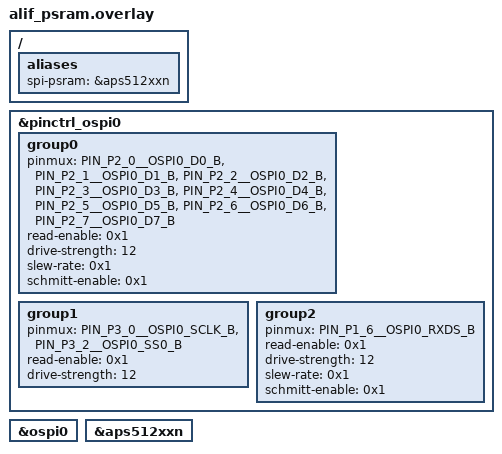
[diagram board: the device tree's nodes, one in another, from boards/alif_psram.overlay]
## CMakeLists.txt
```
cmake_minimum_required(VERSION 3.20.0)
find_package(Zephyr REQUIRED HINTS $ENV{ZEPHYR_BASE})
project(hyperram)

if(CONFIG_TEST_XIP_PERFORMANCE)
  target_sources(app PRIVATE src/performance/test_xip_performance.c)
endif()
if(CONFIG_TEST_XIP_STRESS)
  target_sources(app PRIVATE src/STRESS/test_xip_stress.c)
endif()
if(NOT CONFIG_TEST_XIP_PERFORMANCE AND NOT CONFIG_TEST_XIP_STRESS)
  target_sources(app PRIVATE src/main.c)
endif()
target_sources_ifdef(CONFIG_TEST_PSRAM_FLASH_COPY app PRIVATE src/test_flash_to_psram.c)
target_sources_ifdef(CONFIG_TEST_PSRAM app PRIVATE src/test_hyperram.c)
target_sources_ifdef(CONFIG_TEST_HYPERRAM app PRIVATE src/test_s80ks2564.c)
```

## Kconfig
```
# Copyright (C) 2026 Alif Semiconductor - All Rights Reserved.
# Use, distribution and modification of this code is permitted under the
# terms stated in the Alif Semiconductor Software License Agreement
#
# You should have received a copy of the Alif Semiconductor Software
# License Agreement with this file. If not, please write to:
# contact@alifsemi.com, or visit: https://alifsemi.com/license

choice XIP_DEVICE
	prompt "XIP device under test"
	optional
	default TEST_HYPERRAM
	help
	  Selects which device-specific cases are built on top of the shared
	  XIP suite in src/main.c. HyperRAM (S80KS2564) is the default.
	  Pass CONFIG_TEST_PSRAM=y for the APS512XXN cases, or
	  CONFIG_TEST_ISSI_HYPERRAM=y for the shared suite on ISSI IS66.
	  With neither set, only the shared cases run.

config TEST_PSRAM
	bool "APS512XXN PSRAM"
	help
	  Build src/test_hyperram.c (APS512XXN identity and latency-code vs
	  bus-speed). Use boards/alif_psram.overlay. The shared XIP cases in
	  src/main.c are still built. Select this explicitly for APS512
	  images, including the flash-to-PSRAM copy.

config TEST_HYPERRAM
	bool "S80KS2564 HyperRAM"
	help
	  Build src/test_s80ks2564.c (datasheet identity, tCSM, RWDS, and
	  refresh). Use boards/alif_hex_s80ks.overlay. This is the default
	  device for the suite. The shared XIP cases in src/main.c are
	  still built.

config TEST_ISSI_HYPERRAM
	bool "ISSI IS66 HyperRAM"
	help
	  Run the shared XIP suite only. ISSI IS66 has no latency property,
	  so the S80KS and APS512 files are not built. Use
	  boards/alif_b1_issi_hyperram.overlay on the B1 dev kit.
	  Eight-bit stores are skipped because XiP writes are 16-bit frames.

endchoice

config TEST_PSRAM_FULL_CHIP
	bool "Walk the entire PSRAM in the full-memory XIP test"
	depends on TEST_PSRAM
	help
	  Build only test_full_memory_rw_test, which writes and verifies
	  every byte of DT property size (64 MiB on APS512XXN). The other
	  XIP cases are not registered. Leave disabled for functional CI;
	  enable only on bring-up.

config TEST_HYPERRAM_FULL_CHIP
	bool "Walk the entire HyperRAM in the full-memory XIP test"
	depends on TEST_HYPERRAM
	help
	  Build only test_full_memory_rw_test, which writes and verifies
	  every byte of DT property size (32 MiB on S80KS2564). The other
	  XIP cases are not registered. Leave disabled for functional CI;
	  enable only on bring-up.

config TEST_XIP_PERFORMANCE
	bool "XIP bandwidth and latency tests"
	help
	  Build src/performance/test_xip_performance.c. Leave disabled for
	  the functional suite. The window stays non-cacheable.

config TEST_XIP_STRESS
	bool "XIP stress tests"
	help
	  Build src/STRESS/test_xip_stress.c. Leave disabled for the
	  functional suite. With CONFIG_TEST_PSRAM=y this is the seven
	  stress cases plus the two APS checks.

config TEST_PSRAM_FLASH_COPY
	bool "OSPI flash to PSRAM XiP copy tests"
	help
	  Build the flash-to-PSRAM copy cases next to the XIP suite.
	  PSRAM is boards/alif_psram.overlay. Flash is the ospi-flash snippet.
	  On E8 those are separate controllers (OSPI0 PSRAM, OSPI1 flash).
	  Power management is not used.

config TEST_PSRAM_FLASH_COPY_FULL
	bool "Also copy a preprogrammed 4MB test.bin from flash offset 0"
	depends on TEST_PSRAM_FLASH_COPY
	help
	  Add the sample's 4MB copy. OSPI flash offset 0 must contain the
	  image from gen_test_bin.py --size 4M. Leave disabled for the
	  self-contained suite, which programs its own image at 0x10000.

source "Kconfig.zephyr"
```

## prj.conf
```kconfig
CONFIG_STDOUT_CONSOLE=y
CONFIG_PRINTK=y
CONFIG_LOG=y
CONFIG_ARM_MPU=y
CONFIG_CPU_HAS_CUSTOM_FIXED_SOC_MPU_REGIONS=y
CONFIG_EVENTS=y
CONFIG_MAIN_STACK_SIZE=40960
CONFIG_ZTEST_STACK_SIZE=40960
CONFIG_ZTEST=y

CONFIG_MEMC=y
CONFIG_MEMC_OSPI_ALIF=y
CONFIG_USE_ALIF_HAL_OSPI=y
CONFIG_MEMC_LOG_LEVEL_INF=y

CONFIG_HEAP_MEM_POOL_SIZE=65536
```

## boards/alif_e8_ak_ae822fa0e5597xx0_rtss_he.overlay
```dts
/* Copyright (C) Alif Semiconductor - All Rights Reserved.
 * Use, distribution and modification of this code is permitted under the
 * terms stated in the Alif Semiconductor Software License Agreement
 *
 * You should have received a copy of the Alif Semiconductor Software
 * License Agreement with this file. If not, please write to:
 * contact@alifsemi.com, or visit: https://alifsemi.com/license
 */

/*
 * E8 AppKit HSPI0: 16 data lines + dual RWDS. Applied automatically for
 * alif_e8_ak/.../rtss_he on top of alif_psram.overlay.
 */

&pinctrl {
	pinctrl_ospi0:pinctrl_ospi0 {
		group0 {
			pinmux = < PIN_P2_0__OSPI0_D0_B >,
				 < PIN_P2_1__OSPI0_D1_B >,
				 < PIN_P2_2__OSPI0_D2_B >,
				 < PIN_P2_3__OSPI0_D3_B >,
				 < PIN_P2_4__OSPI0_D4_B >,
				 < PIN_P2_5__OSPI0_D5_B >,
				 < PIN_P2_6__OSPI0_D6_B >,
				 < PIN_P2_7__OSPI0_D7_B >,
				 < PIN_P16_0__OSPI0_D8_B >,
				 < PIN_P16_1__OSPI0_D9_B >,
				 < PIN_P16_2__OSPI0_D10_B >,
				 < PIN_P16_3__OSPI0_D11_B >,
				 < PIN_P16_4__OSPI0_D12_B >,
				 < PIN_P16_5__OSPI0_D13_B >,
				 < PIN_P16_6__OSPI0_D14_B >,
				 < PIN_P16_7__OSPI0_D15_B >;
			read-enable = <0x1>;
			drive-strength = <12>;
			slew-rate = <0x1>;
			schmitt-enable = <0x1>;
		};
		group1 {
			pinmux = < PIN_P3_0__OSPI0_SCLK_B >,
				 < PIN_P3_2__OSPI0_SS0_B >;
			read-enable = <0x1>;
			drive-strength = <12>;
		};
		group2 {
			pinmux = < PIN_P1_6__OSPI0_RXDS_B >,
				 < PIN_P8_5__OSPI0_RXDS1_A >;
			read-enable = <0x1>;
			drive-strength = <12>;
			slew-rate = <0x1>;
			schmitt-enable = <0x1>;
		};
	};
};

&aps512xxn {
	x16-data-transfer-mode;
};
```

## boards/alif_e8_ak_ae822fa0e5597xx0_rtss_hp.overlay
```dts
/* Copyright (C) Alif Semiconductor - All Rights Reserved.
 * Use, distribution and modification of this code is permitted under the
 * terms stated in the Alif Semiconductor Software License Agreement
 *
 * You should have received a copy of the Alif Semiconductor Software
 * License Agreement with this file. If not, please write to:
 * contact@alifsemi.com, or visit: https://alifsemi.com/license
 */

/*
 * E8 AppKit HSPI0: 16 data lines + dual RWDS. Applied automatically for
 * alif_e8_ak/.../rtss_hp on top of alif_psram.overlay.
 */

&pinctrl {
	pinctrl_ospi0:pinctrl_ospi0 {
		group0 {
			pinmux = < PIN_P2_0__OSPI0_D0_B >,
				 < PIN_P2_1__OSPI0_D1_B >,
				 < PIN_P2_2__OSPI0_D2_B >,
				 < PIN_P2_3__OSPI0_D3_B >,
				 < PIN_P2_4__OSPI0_D4_B >,
				 < PIN_P2_5__OSPI0_D5_B >,
				 < PIN_P2_6__OSPI0_D6_B >,
				 < PIN_P2_7__OSPI0_D7_B >,
				 < PIN_P16_0__OSPI0_D8_B >,
				 < PIN_P16_1__OSPI0_D9_B >,
				 < PIN_P16_2__OSPI0_D10_B >,
				 < PIN_P16_3__OSPI0_D11_B >,
				 < PIN_P16_4__OSPI0_D12_B >,
				 < PIN_P16_5__OSPI0_D13_B >,
				 < PIN_P16_6__OSPI0_D14_B >,
				 < PIN_P16_7__OSPI0_D15_B >;
			read-enable = <0x1>;
			drive-strength = <12>;
			slew-rate = <0x1>;
			schmitt-enable = <0x1>;
		};
		group1 {
			pinmux = < PIN_P3_0__OSPI0_SCLK_B >,
				 < PIN_P3_2__OSPI0_SS0_B >;
			read-enable = <0x1>;
			drive-strength = <12>;
		};
		group2 {
			pinmux = < PIN_P1_6__OSPI0_RXDS_B >,
				 < PIN_P8_5__OSPI0_RXDS1_A >;
			read-enable = <0x1>;
			drive-strength = <12>;
			slew-rate = <0x1>;
			schmitt-enable = <0x1>;
		};
	};
};

&aps512xxn {
	x16-data-transfer-mode;
};
```

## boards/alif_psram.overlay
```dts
/* Copyright (C) Alif Semiconductor - All Rights Reserved.
 * Use, distribution and modification of this code is permitted under the
 * terms stated in the Alif Semiconductor Software License Agreement
 *
 * You should have received a copy of the Alif Semiconductor Software
 * License Agreement with this file. If not, please write to:
 * contact@alifsemi.com, or visit: https://alifsemi.com/license
 */

/*
 * For OSPI0 Test with APS512XXN RAM
 */

/ {
	aliases {
		spi-psram = &aps512xxn;
	};
};

&pinctrl_ospi0 {
	group0 {
		pinmux = <PIN_P2_0__OSPI0_D0_B>,
			 <PIN_P2_1__OSPI0_D1_B>,
			 <PIN_P2_2__OSPI0_D2_B>,
			 <PIN_P2_3__OSPI0_D3_B>,
			 <PIN_P2_4__OSPI0_D4_B>,
			 <PIN_P2_5__OSPI0_D5_B>,
			 <PIN_P2_6__OSPI0_D6_B>,
			 <PIN_P2_7__OSPI0_D7_B>;
		read-enable = <0x1>;
		drive-strength = <12>;
		slew-rate = <0x1>;
		schmitt-enable = <0x1>;
	};
	group1 {
		pinmux = <PIN_P3_0__OSPI0_SCLK_B>,
			 <PIN_P3_2__OSPI0_SS0_B>;
		read-enable = <0x1>;
		drive-strength = <12>;
	};
	group2 {
		pinmux = <PIN_P1_6__OSPI0_RXDS_B>;
		read-enable = <0x1>;
		drive-strength = <12>;
		slew-rate = <0x1>;
		schmitt-enable = <0x1>;
	};
};

&ospi0 {
	status = "okay";
};

&aps512xxn {
	status = "okay";
};
```

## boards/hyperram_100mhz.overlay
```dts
/* Layer on boards/alif_hex_s80ks.overlay.
 * LC4 is valid to 104 MHz (S80KS2564 CR0[7:4], tACC 35 ns).
 */

&ospi1 {
	bus-speed = <100000000>;
};

&s80ks2564 {
	latency = <4>;
};
```

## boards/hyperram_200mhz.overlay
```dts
/* Layer on boards/alif_hex_s80ks.overlay.
 * 200 MHz requires latency 7 (S80KS2564 CR0[7:4], tACC 35 ns).
 */

&ospi1 {
	bus-speed = <200000000>;
};

&s80ks2564 {
	latency = <7>;
};
```

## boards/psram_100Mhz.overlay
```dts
/* Copyright (C) Alif Semiconductor - All Rights Reserved.
 * Use, distribution and modification of this code is permitted under the
 * terms stated in the Alif Semiconductor Software License Agreement
 *
 * You should have received a copy of the Alif Semiconductor Software
 * License Agreement with this file. If not, please write to:
 * contact@alifsemi.com, or visit: https://alifsemi.com/license
 */

/* Layer on boards/alif_psram.overlay. Latency code 4 is valid up to 109 MHz. */

&ospi0 {
	bus-speed = <100000000>;
};

&aps512xxn {
	latency-code = <4>;
};
```

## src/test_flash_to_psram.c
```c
/* Copyright (C) 2026 Alif Semiconductor - All Rights Reserved.
 * Use, distribution and modification of this code is permitted under the
 * terms stated in the Alif Semiconductor Software License Agreement
 *
 * You should have received a copy of the Alif Semiconductor Software
 * License Agreement with this file. If not, please write to:
 * contact@alifsemi.com, or visit: https://alifsemi.com/license
 */

/*
 * Copy an OSPI flash image into the PSRAM XiP window and check the same
 * layout as samples/drivers/spi_flash_to_psram_copy (ALIFPSRM magic,
 * offset-encoded words, CRC32 tail).
 *
 * PSRAM comes from boards/alif_psram.overlay (OSPI0, APS512XXN). Flash comes
 * from the ospi-flash snippet (OSPI1 on E8). The two devices are on separate
 * controllers, so the copy is flash_read() into the PSRAM XiP window. No
 * AIPM / power-management overlay is used.
 */

#include <string.h>

#include <zephyr/device.h>
#include <zephyr/devicetree.h>
#include <zephyr/drivers/flash.h>
#include <zephyr/kernel.h>
#include <zephyr/logging/log.h>
#include <zephyr/sys/crc.h>
#include <zephyr/sys/util.h>
#include <zephyr/ztest.h>

#if !DT_HAS_ALIAS(spi_psram)
#error "Devicetree alias spi-psram is required (boards/alif_psram.overlay)"
#endif

#if !DT_HAS_ALIAS(spi_flash0)
#error "Devicetree alias spi-flash0 is required (snippet ospi-flash)"
#endif

LOG_MODULE_REGISTER(hyperram_flash_copy, LOG_LEVEL_INF);

#define FLASH_NODE        DT_ALIAS(spi_flash0)
#define PSRAM_NODE        DT_ALIAS(spi_psram)
#define PSRAM_CTRL_NODE   DT_PARENT(PSRAM_NODE)

#define FLASH_SECTOR_SIZE DT_PROP(FLASH_NODE, sector_size)
/* 1 KiB image. Erase is still one full sector; the driver rejects a short erase. */
#define COPY_TEST_BYTES   1024U
#define COPY_CHUNK        1024U
#define COPY_FLASH_OFF    0x10000
#define COPY_PSRAM_OFF    0x0
#define COPY_PSRAM_OFF2   0x20000

#define PSRAM_XIP_BASE    ((uintptr_t)DT_PROP_BY_IDX(PSRAM_CTRL_NODE, xip_base_address, 0))
#define PSRAM_XIP_SIZE    ((size_t)DT_PROP_BY_IDX(PSRAM_CTRL_NODE, xip_base_address, 1))
#define PSRAM_DEV_SIZE    ((size_t)DT_PROP(PSRAM_NODE, size))
#define PSRAM_USABLE      MIN(PSRAM_XIP_SIZE, PSRAM_DEV_SIZE)

#define TEST_MAGIC        "ALIFPSRM"
#define TEST_MAGIC_LEN    8U

static const struct device *const flash_dev = DEVICE_DT_GET(FLASH_NODE);
static const struct device *const psram_dev = DEVICE_DT_GET(PSRAM_NODE);
static uint8_t test_image[COPY_TEST_BYTES];

static void build_test_image(uint8_t *buf, size_t size)
{
	uint32_t crc;

	memset(buf, 0, size);
	memcpy(buf, TEST_MAGIC, TEST_MAGIC_LEN);

	for (size_t off = TEST_MAGIC_LEN; off < (size - 4U); off += 4U) {
		uint32_t word = (uint32_t)off;

		memcpy(buf + off, &word, sizeof(word));
	}

	crc = crc32_ieee(buf, size - 4U);
	memcpy(buf + (size - 4U), &crc, sizeof(crc));
}

static bool range_ok(off_t psram_off, size_t len)
{
	if (psram_off < 0 || (size_t)psram_off > PSRAM_USABLE) {
		return false;
	}

	return len <= (PSRAM_USABLE - (size_t)psram_off);
}

/* flash_read() into the PSRAM XiP window. Length and offset are word aligned. */
static int flash_to_psram_copy(off_t flash_off, off_t psram_off, size_t len)
{
	uint8_t chunk[COPY_CHUNK];

	if (len == 0U) {
		return 0;
	}

	if ((len % 4U) != 0U || (psram_off % 4) != 0 || !range_ok(psram_off, len)) {
		return -EINVAL;
	}

	for (size_t done = 0; done < len; done += COPY_CHUNK) {
		size_t n = MIN((size_t)COPY_CHUNK, len - done);
		volatile uint32_t *dst;
		const uint32_t *src;
		int ret;

		ret = flash_read(flash_dev, flash_off + (off_t)done, chunk, n);
		if (ret != 0) {
			return ret;
		}

		dst = (volatile uint32_t *)(PSRAM_XIP_BASE + (uintptr_t)psram_off + done);
		if (done == 0U) {
			LOG_INF("flash read ok, first store at 0x%08lx",
				(unsigned long)(uintptr_t)dst);
		}
		src = (const uint32_t *)chunk;
		for (size_t i = 0; i < (n / sizeof(uint32_t)); i++) {
			dst[i] = src[i];
		}
	}

	return 0;
}

static int flash_to_psram_verify(off_t psram_off, size_t len)
{
	const uint8_t *base = (const uint8_t *)(PSRAM_XIP_BASE + (uintptr_t)psram_off);
	uint32_t calc_crc;
	uint32_t trailer;

	if (len < (TEST_MAGIC_LEN + 4U) || (len % 4U) != 0U || !range_ok(psram_off, len)) {
		return -EINVAL;
	}

	if (memcmp(base, TEST_MAGIC, TEST_MAGIC_LEN) != 0) {
		LOG_INF("verify: magic FAIL (got %02x %02x %02x %02x)",
			base[0], base[1], base[2], base[3]);
		return -EIO;
	}

	for (size_t off = TEST_MAGIC_LEN; off < (len - 4U); off += 4U) {
		uint32_t word;

		memcpy(&word, base + off, sizeof(word));
		if (word != (uint32_t)off) {
			LOG_INF("verify: pattern FAIL @0x%zx exp 0x%08x got 0x%08x",
				off, (uint32_t)off, word);
			return -EIO;
		}
	}

	calc_crc = crc32_ieee(base, len - 4U);
	memcpy(&trailer, base + (len - 4U), sizeof(trailer));
	if (calc_crc != trailer) {
		LOG_INF("verify: crc32 FAIL (calc 0x%08x, stored 0x%08x)", calc_crc, trailer);
		return -EIO;
	}

	LOG_INF("verify: PASS -- %zu bytes at PSRAM XiP 0x%08lx",
		len, (unsigned long)(uintptr_t)base);
	return 0;
}

static void program_test_image(void)
{
	uint8_t readback[256];
	int ret;

	ret = flash_erase(flash_dev, COPY_FLASH_OFF, FLASH_SECTOR_SIZE);
	zassert_equal(ret, 0, "flash_erase @0x%x failed: %d", COPY_FLASH_OFF, ret);

	ret = flash_write(flash_dev, COPY_FLASH_OFF, test_image, sizeof(test_image));
	zassert_equal(ret, 0, "flash_write @0x%x failed: %d", COPY_FLASH_OFF, ret);

	for (size_t off = 0; off < sizeof(test_image); off += sizeof(readback)) {
		size_t n = MIN(sizeof(readback), sizeof(test_image) - off);

		ret = flash_read(flash_dev, COPY_FLASH_OFF + (off_t)off, readback, n);
		zassert_equal(ret, 0, "flash_read @0x%zx failed: %d",
				  (size_t)COPY_FLASH_OFF + off, ret);
		zassert_mem_equal(readback, &test_image[off], n,
				  "flash readback mismatch at image offset 0x%zx", off);
	}
}

static void assert_psram_matches(off_t psram_off, const char *tag)
{
	const uint8_t *xip = (const uint8_t *)(PSRAM_XIP_BASE + (uintptr_t)psram_off);
	int ret;

	ret = flash_to_psram_verify(psram_off, sizeof(test_image));
	zassert_equal(ret, 0, "%s: verify failed: %d", tag, ret);

	for (size_t off = 0; off < sizeof(test_image); off += sizeof(uint32_t)) {
		uint32_t got;
		uint32_t exp;

		memcpy(&got, xip + off, sizeof(got));
		memcpy(&exp, &test_image[off], sizeof(exp));
		zassert_equal(got, exp, "%s: mismatch at 0x%zx exp 0x%08x got 0x%08x",
				  tag, off, exp, got);
	}
}

static void *flash_copy_setup(void)
{
	LOG_INF("flash -> PSRAM copy (image %u bytes, flash 0x%x, XiP 0x%08lx)",
		(unsigned int)sizeof(test_image), COPY_FLASH_OFF,
		(unsigned long)PSRAM_XIP_BASE);

	zassert_true(device_is_ready(psram_dev), "PSRAM %s is not ready", psram_dev->name);
	zassert_true(device_is_ready(flash_dev), "OSPI flash %s is not ready", flash_dev->name);

	build_test_image(test_image, sizeof(test_image));
	program_test_image();
	return NULL;
}

ZTEST(hyperram_flash_copy, test_copy_rejects_bad_args)
{
	size_t too_big = PSRAM_USABLE + 4U;

	LOG_INF("=== reject bad copy/verify arguments ===");

	zassert_equal(flash_to_psram_copy(0, 0, 0), 0, "zero-length copy should succeed");
	zassert_equal(flash_to_psram_copy(COPY_FLASH_OFF, 1, 16), -EINVAL,
			  "unaligned PSRAM offset must be rejected");
	zassert_equal(flash_to_psram_copy(COPY_FLASH_OFF, 0, 2), -EINVAL,
			  "length that is not word aligned must be rejected");
	zassert_equal(flash_to_psram_copy(COPY_FLASH_OFF, 0, too_big), -EINVAL,
			  "copy past the PSRAM window must be rejected");

	zassert_equal(flash_to_psram_verify(0, 8), -EINVAL,
			  "verify shorter than magic + CRC must be rejected");
	zassert_equal(flash_to_psram_verify(0, 14), -EINVAL,
			  "verify length that is not word aligned must be rejected");
	zassert_equal(flash_to_psram_verify(0, too_big), -EINVAL,
			  "verify past the PSRAM window must be rejected");
}

ZTEST(hyperram_flash_copy, test_copy_and_verify_image)
{
	int ret;

	LOG_INF("=== copy %u bytes flash@0x%x -> psram@0x%x ===",
		(unsigned int)sizeof(test_image), COPY_FLASH_OFF, COPY_PSRAM_OFF);

	ret = flash_to_psram_copy(COPY_FLASH_OFF, COPY_PSRAM_OFF, sizeof(test_image));
	zassert_equal(ret, 0, "copy failed: %d", ret);

	assert_psram_matches(COPY_PSRAM_OFF, "psram@0");
	LOG_INF("copy and verify PASSED");
}

ZTEST(hyperram_flash_copy, test_copy_second_region_keeps_first)
{
	int ret;

	LOG_INF("=== second copy to psram@0x%x leaves the first region intact ===",
		COPY_PSRAM_OFF2);

	ret = flash_to_psram_copy(COPY_FLASH_OFF, COPY_PSRAM_OFF, sizeof(test_image));
	zassert_equal(ret, 0, "first copy failed: %d", ret);

	ret = flash_to_psram_copy(COPY_FLASH_OFF, COPY_PSRAM_OFF2, sizeof(test_image));
	zassert_equal(ret, 0, "second copy failed: %d", ret);

	assert_psram_matches(COPY_PSRAM_OFF2, "psram@0x20000");
	assert_psram_matches(COPY_PSRAM_OFF, "psram@0 after second copy");
	LOG_INF("second-region copy PASSED");
}

#if IS_ENABLED(CONFIG_TEST_PSRAM_FLASH_COPY_FULL)
/* Same check as the sample: first 4MB of OSPI flash. Requires test.bin from
 * gen_test_bin.py --size 4M programmed at flash offset 0.
 */
ZTEST(hyperram_flash_copy, test_copy_preprogrammed_4mb)
{
	const size_t len = 4U * 1024U * 1024U;
	int ret;

	LOG_INF("=== copy preprogrammed 4MB test.bin ===");

	ret = flash_to_psram_copy(0, 0, len);
	zassert_equal(ret, 0, "4MB copy failed: %d", ret);

	ret = flash_to_psram_verify(0, len);
	zassert_equal(ret, 0,
			  "4MB verify failed (%d). Program test.bin from "
			  "gen_test_bin.py --size 4M at OSPI flash offset 0",
			  ret);
}
#endif

ZTEST_SUITE(hyperram_flash_copy, NULL, flash_copy_setup, NULL, NULL, NULL);
```

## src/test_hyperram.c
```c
/* Copyright (C) 2026 Alif Semiconductor - All Rights Reserved.
 * Use, distribution and modification of this code is permitted under the
 * terms stated in the Alif Semiconductor Software License Agreement
 *
 * You should have received a copy of the Alif Semiconductor Software
 * License Agreement with this file. If not, please write to:
 * contact@alifsemi.com, or visit: https://alifsemi.com/license
 *
 * APS512XXN checks. Built only when CONFIG_TEST_PSRAM=y.
 * The suite default is CONFIG_TEST_HYPERRAM (src/test_s80ks2564.c).
 */

#include <zephyr/devicetree.h>
#include <zephyr/logging/log.h>
#include <zephyr/sys/util.h>
#include <zephyr/ztest.h>

#if !DT_HAS_ALIAS(spi_psram)
#error "Devicetree alias spi-psram is required"
#endif

LOG_MODULE_DECLARE(xip);

#define APS_NODE        DT_ALIAS(spi_psram)
#define APS_CTRL        DT_PARENT(APS_NODE)
#define APS_SIZE        ((uint32_t)DT_PROP(APS_NODE, size))
#define APS_LATENCY     ((uint32_t)DT_PROP(APS_NODE, latency_code))
#define APS_BUS_HZ      ((uint32_t)DT_PROP(APS_CTRL, bus_speed))
#define APS_XIP_BASE    ((uint32_t)DT_PROP_BY_IDX(APS_CTRL, xip_base_address, 0))
#define APS_XIP_WIN     ((uint32_t)DT_PROP_BY_IDX(APS_CTRL, xip_base_address, 1))
#define APS_SIZE_512MBIT (64U * 1024U * 1024U)

#if !IS_ENABLED(CONFIG_TEST_PSRAM_FULL_CHIP)

/* latency-code vs max CLK from the APS512XXN binding. */
static uint32_t aps_max_hz_for_latency(uint32_t lc)
{
	switch (lc) {
	case 3:
		return 66000000U;
	case 4:
		return 109000000U;
	case 5:
		return 133000000U;
	case 6:
		return 166000000U;
	case 7:
		return 200000000U;
	default:
		return 0U;
	}
}

ZTEST(xip_tests, test_aps512_dt_identity)
{
	zassert_true(DT_NODE_HAS_COMPAT(APS_NODE, alif_apmemory_aps512xxn),
			 "spi-psram is not alif,apmemory-aps512xxn");
	zassert_equal(APS_SIZE, APS_SIZE_512MBIT,
			  "size %u, expected 64 MB (512 Mbit)", APS_SIZE);
	zassert_true(APS_XIP_BASE != 0U, "XIP base is 0");
	zassert_true(APS_SIZE <= APS_XIP_WIN,
			 "size %u exceeds XIP window %u", APS_SIZE, APS_XIP_WIN);
	zassert_true(APS_BUS_HZ > 0U && APS_BUS_HZ <= 200000000U,
			 "bus-speed %u Hz outside 1..200 MHz", APS_BUS_HZ);
}

ZTEST(xip_tests, test_aps512_latency_code_vs_frequency)
{
	uint32_t max_hz = aps_max_hz_for_latency(APS_LATENCY);

	LOG_INF("APS512XXN DT: bus-speed %u Hz, latency-code %u, max %u Hz",
		APS_BUS_HZ, APS_LATENCY, max_hz);

	zassert_true(APS_LATENCY >= 3U && APS_LATENCY <= 7U,
			 "latency-code %u not in 3-7", APS_LATENCY);
	zassert_true(max_hz > 0U, "reserved latency-code %u", APS_LATENCY);
	zassert_true(APS_BUS_HZ <= max_hz,
			 "bus-speed %u Hz exceeds latency-code %u max %u Hz",
			 APS_BUS_HZ, APS_LATENCY, max_hz);
}

#endif /* !CONFIG_TEST_PSRAM_FULL_CHIP */
```

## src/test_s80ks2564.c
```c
/* Copyright (C) 2026 Alif Semiconductor - All Rights Reserved.
 * Use, distribution and modification of this code is permitted under the
 * terms stated in the Alif Semiconductor Software License Agreement
 *
 * You should have received a copy of the Alif Semiconductor Software
 * License Agreement with this file. If not, please write to:
 * contact@alifsemi.com, or visit: https://alifsemi.com/license
 *
 * S80KS2564 datasheet checks. Overlay/test only — does not change the MEMC
 * driver. Accesses are chunked so CS# can rise before tCSM (4 µs at ≤85 °C).
 */

#include <zephyr/device.h>
#include <zephyr/devicetree.h>
#include <zephyr/kernel.h>
#include <zephyr/logging/log.h>
#include <zephyr/sys/util.h>
#include <zephyr/ztest.h>

#if !DT_HAS_ALIAS(spi_psram)
#error "Devicetree alias spi-psram is required (boards/alif_hex_s80ks.overlay)"
#endif

LOG_MODULE_DECLARE(xip);

#define S80KS_NODE              DT_ALIAS(spi_psram)
#define S80KS_CTRL              DT_PARENT(S80KS_NODE)
#define S80KS_SIZE              ((uint32_t)DT_PROP(S80KS_NODE, size))
#define S80KS_LATENCY           ((uint32_t)DT_PROP(S80KS_NODE, latency))
#define S80KS_BUS_HZ            ((uint32_t)DT_PROP(S80KS_CTRL, bus_speed))
#define S80KS_XIP_BASE          ((uint32_t)DT_PROP_BY_IDX(S80KS_CTRL, \
							  xip_base_address, 0))

/*
 * tCSM = 4 µs (grade 3, TA ≤ 85 °C). 64 words = 256 bytes:
 * ~0.3 µs at 200 MHz DDR x16, ~1.6 µs at 40 MHz.
 * After each chunk, stay off this window for a few microseconds so the
 * MEMC can raise CS#.
 */
#define S80KS_TCSM_CHUNK_WORDS  64U
#define S80KS_TCSM_IDLE_US      5U

#if !IS_ENABLED(CONFIG_TEST_HYPERRAM_FULL_CHIP)

static uint32_t s80ks_max_hz_for_latency(uint32_t lc)
{
	switch (lc) {
	case 3:
		return 85000000U;
	case 4:
		return 104000000U;
	case 5:
		return 133000000U;
	case 6:
		return 166000000U;
	case 7:
		return 200000000U;
	default:
		return 0U;
	}
}

static void s80ks_tcsm_gap(void)
{
	k_busy_wait(S80KS_TCSM_IDLE_US);
}

static void s80ks_fill_u32(volatile uint32_t *ptr, uint32_t n, uint32_t seed)
{
	for (uint32_t i = 0; i < n; i++) {
		ptr[i] = seed + i;
		if (((i + 1U) % S80KS_TCSM_CHUNK_WORDS) == 0U) {
			s80ks_tcsm_gap();
		}
	}
	s80ks_tcsm_gap();
}

static int s80ks_check_u32(volatile uint32_t *ptr, uint32_t n, uint32_t seed)
{
	int errors = 0;

	for (uint32_t i = 0; i < n; i++) {
		uint32_t expected = seed + i;
		uint32_t got = ptr[i];

		if (got != expected) {
			errors++;
			if (errors <= 5) {
				LOG_INF("word %u: exp 0x%08x got 0x%08x",
					i, expected, got);
			}
		}
		if (((i + 1U) % S80KS_TCSM_CHUNK_WORDS) == 0U) {
			s80ks_tcsm_gap();
		}
	}
	s80ks_tcsm_gap();
	return errors;
}

/*
 * CR0[7:4] vs clock (tACC 35 ns):
 * LC3 ≤85 MHz, LC4 ≤104, LC5 ≤133, LC6 ≤166, LC7 ≤200 (default).
 */
ZTEST(xip_tests, test_s80ks_latency_vs_frequency)
{
	uint32_t max_hz = s80ks_max_hz_for_latency(S80KS_LATENCY);

	LOG_INF("S80KS2564 DT: bus-speed %u Hz, latency %u, max for LC %u Hz",
		S80KS_BUS_HZ, S80KS_LATENCY, max_hz);

	zassert_true(S80KS_LATENCY >= 3U && S80KS_LATENCY <= 7U,
			 "latency %u not in CR0 range 3-7", S80KS_LATENCY);
	zassert_true(max_hz > 0U, "reserved latency code %u", S80KS_LATENCY);
	zassert_true(S80KS_BUS_HZ <= max_hz,
			 "bus-speed %u Hz exceeds LC%u max %u Hz "
			 "(200 MHz requires latency 7)",
			 S80KS_BUS_HZ, S80KS_LATENCY, max_hz);
}

/* Native bus is DQ[15:0]; halfword is one HyperBus beat. */
ZTEST(xip_tests, test_s80ks_x16_walking_bits)
{
	volatile uint16_t *ptr = (volatile uint16_t *)S80KS_XIP_BASE;

	LOG_INF("=== S80KS x16 walking-1/0 on DQ[15:0] ===");

	for (int bit = 0; bit < 16; bit++) {
		ptr[bit] = (uint16_t)BIT(bit);
		s80ks_tcsm_gap();
	}
	for (int bit = 0; bit < 16; bit++) {
		uint16_t expected = (uint16_t)BIT(bit);
		uint16_t got = ptr[bit];

		s80ks_tcsm_gap();
		zassert_equal(got, expected,
				  "DQ[%d] walking-1: wrote 0x%04x read 0x%04x",
				  bit, expected, got);
	}

	for (int bit = 0; bit < 16; bit++) {
		ptr[bit] = (uint16_t)(~BIT(bit) & 0xFFFF);
		s80ks_tcsm_gap();
	}
	for (int bit = 0; bit < 16; bit++) {
		uint16_t expected = (uint16_t)(~BIT(bit) & 0xFFFF);
		uint16_t got = ptr[bit];

		s80ks_tcsm_gap();
		zassert_equal(got, expected,
				  "DQ[%d] walking-0: wrote 0x%04x read 0x%04x",
				  bit, expected, got);
	}
}

/* DDR: two 16-bit beats per CK. Alternating 0x5555/0xAAAA stresses both edges. */
ZTEST(xip_tests, test_s80ks_ddr_beat_patterns)
{
	volatile uint32_t *ptr = (volatile uint32_t *)S80KS_XIP_BASE;
	const uint32_t patterns[] = {
		0x5555AAAAU, 0xAAAA5555U, 0x00FF00FFU, 0xFF00FF00U,
	};
	const uint32_t n = 256;

	LOG_INF("=== S80KS DDR beat patterns ===");

	for (int p = 0; p < ARRAY_SIZE(patterns); p++) {
		for (uint32_t i = 0; i < n; i++) {
			ptr[i] = patterns[p];
			if (((i + 1U) % S80KS_TCSM_CHUNK_WORDS) == 0U) {
				s80ks_tcsm_gap();
			}
		}
		s80ks_tcsm_gap();
		for (uint32_t i = 0; i < n; i++) {
			uint32_t got = ptr[i];

			if (((i + 1U) % S80KS_TCSM_CHUNK_WORDS) == 0U) {
				s80ks_tcsm_gap();
			}
			zassert_equal(got, patterns[p],
					  "DDR 0x%08x failed at word %u: got 0x%08x",
					  patterns[p], i, got);
		}
	}
}

/*
 * Linear burst (CA[45]=1): sequential words across row boundaries.
 * Chunked to keep each CS# window under tCSM.
 */
ZTEST(xip_tests, test_s80ks_linear_burst_under_tcsm)
{
	volatile uint32_t *ptr = (volatile uint32_t *)S80KS_XIP_BASE;
	const uint32_t n = 2048; /* 8 KB, several row crossings */
	const uint32_t seed = 0x1B000000U;
	int errors;

	LOG_INF("=== S80KS linear burst (%u words, tCSM gaps) ===", n);
	s80ks_fill_u32(ptr, n, seed);
	errors = s80ks_check_u32(ptr, n, seed);
	zassert_equal(errors, 0, "linear burst failed: %d errors", errors);
}

/*
 * Host must end the burst so refresh can run, then start a new transaction.
 * Gap is >> tCSM so distributed refresh must have had a chance.
 */
ZTEST(xip_tests, test_s80ks_refresh_between_transactions)
{
	volatile uint32_t *ptr = (volatile uint32_t *)S80KS_XIP_BASE;
	const uint32_t n = 512;
	const uint32_t seed = 0xDA7A0000U;
	int errors;

	LOG_INF("=== S80KS refresh gap (tCSM / distributed refresh) ===");
	s80ks_fill_u32(ptr, n, seed);
	k_busy_wait(20); /* several tCSM intervals with CS# idle */
	errors = s80ks_check_u32(ptr, n, seed);
	zassert_equal(errors, 0,
			  "data lost across refresh gap: %d errors", errors);
}

/* RWDS is write-mask on writes; byte stores must not corrupt neighbors. */
ZTEST(xip_tests, test_s80ks_rwds_byte_mask)
{
	volatile uint8_t *bp = (volatile uint8_t *)S80KS_XIP_BASE;
	volatile uint32_t *wp = (volatile uint32_t *)S80KS_XIP_BASE;

	LOG_INF("=== S80KS RWDS byte mask ===");

	*wp = 0xA5A5A5A5U;
	s80ks_tcsm_gap();
	bp[1] = 0x5AU;
	s80ks_tcsm_gap();

	zassert_equal(bp[0], 0xA5, "byte0 corrupted by masked write");
	zassert_equal(bp[1], 0x5A, "byte1 mask write failed");
	zassert_equal(bp[2], 0xA5, "byte2 corrupted by masked write");
	zassert_equal(bp[3], 0xA5, "byte3 corrupted by masked write");
}

/*
 * If XIP uses wrapped burst (CA[45]=0) with 16-word wrap, word 16 overwrites
 * word 0. Linear INCR must not wrap. One tight burst, no tCSM gap: a gap
 * would end CS# and hide the wrap.
 */
ZTEST(xip_tests, test_s80ks_no_16word_wrap)
{
	volatile uint16_t *ptr = (volatile uint16_t *)S80KS_XIP_BASE;
	uint16_t word0;
	uint16_t word16;

	LOG_INF("=== S80KS 16-word wrap vs linear ===");

	for (int i = 0; i < 32; i++) {
		ptr[i] = (uint16_t)(0xA000U + i);
	}

	word0 = ptr[0];
	word16 = ptr[16];
	zassert_equal(word0, (uint16_t)0xA000U,
			  "word 0: exp 0x%04x got 0x%04x (16-word wrap aliases word 16)",
			  0xA000U, word0);
	zassert_equal(word16, (uint16_t)(0xA000U + 16U),
			  "word 16: exp 0x%04x got 0x%04x (16-word wrap aliases word 0)",
			  0xA000U + 16U, word16);
}

/* 1/8, 1/4, 1/2, full array offsets (datasheet partial-array refresh regions). */
ZTEST(xip_tests, test_s80ks_partial_array_offsets)
{
	const uint32_t frac[] = {8, 4, 2, 1};
	int total = 0;

	LOG_INF("=== S80KS partial-array offsets ===");

	for (int f = 0; f < ARRAY_SIZE(frac); f++) {
		uint32_t region = S80KS_SIZE / frac[f];
		uint32_t off = (frac[f] == 1U) ? 0U : (S80KS_SIZE - region);
		volatile uint32_t *ptr = (volatile uint32_t *)(S80KS_XIP_BASE + off);
		uint32_t seed = 0x3A000000U | ((uint32_t)f << 16);
		int errors;

		LOG_INF("1/%u at offset 0x%08x", frac[f], off);
		s80ks_fill_u32(ptr, 64, seed);
		errors = s80ks_check_u32(ptr, 64, seed);
		total += errors;
	}

	zassert_equal(total, 0, "partial-array offset R/W failed: %d errors", total);
}

#endif /* !CONFIG_TEST_HYPERRAM_FULL_CHIP */
```
